VERSION ""

NS_ :

BS_:

BU_: VESC1 Main_ECU

BO_ 2147483649 VESC_Command_DutyCycle_V1: 4 Main_ECU
 SG_ Command_DutyCycle_V1 : 7|32@0- (0.001,0) [-100|100] "%"  VESC1

BO_ 2147486721 VESC_Command_AbsHBrakeCurrent_V1: 8 Main_ECU
 SG_ Command_HBrakeCurrent_V1 : 7|32@0- (0.001,0) [-2147483.648|2147483.647] "mA"  VESC1

BO_ 2147486977 VESC_Command_RelHBrakeCurrent_V1: 8 Main_ECU
 SG_ Command_RelativeHBrakeCurrent_V1 : 7|32@0- (0.001,0) [-100|100] "%"  VESC1

BO_ 2147489281 VESC_Set_CurrentLimitPerm_V1: 8 Main_ECU
 SG_ Setting_CurrentLimitMin_V1 : 7|32@0- (0.001,0) [-2147483.648|2147483.647] ""  VESC1
 SG_ Setting_CurrentLimitMax_V1 : 39|32@0- (0.001,0) [-2147483.648|2147483.647] ""  VESC1

BO_ 2147489025 VESC_Set_CurrentLimitTemp_V1: 8 Main_ECU
 SG_ Setting_CurrentLimitMin_V1 : 7|32@0- (0.001,0) [-2147483.648|2147483.647] ""  VESC1
 SG_ Setting_CurrentLimitMax_V1 : 39|32@0- (0.001,0) [-2147483.648|2147483.647] ""  VESC1

BO_ 2147486465 VESC_Command_RelBrakeCurrent_V1: 4 Main_ECU
 SG_ Command_RelativeBrakeCurrent_V1 : 7|32@0- (0.001,0) [-100|100] "%"  VESC1

BO_ 2147486209 VESC_Command_RelCurrent_V1: 4 Main_ECU
 SG_ Command_RelativeCurrent_V1 : 7|32@0- (0.001,0) [-100|100] "%"  VESC1

BO_ 2147484673 VESC_Command_POS_V1: 4 Main_ECU
 SG_ Command_POS_V1 : 7|32@0- (1,0) [-2147483648|2147483647] "RPM"  VESC1

BO_ 2147484161 VESC_Command_AbsBrakeCurrent_V1: 4 Main_ECU
 SG_ Command_BrakeCurrent_V1 : 7|32@0- (0.001,0) [-2147483.648|2147483.647] "mA"  VESC1

BO_ 2147483905 VESC_Command_AbsCurrent_V1: 4 Main_ECU
 SG_ Command_Current_V1 : 7|32@0- (0.001,0) [-2147483.648|2147483.647] "mA"  VESC1

BO_ 2147484417 VESC_Command_RPM_V1: 4 Main_ECU
 SG_ Command_RPM_V1 : 7|32@0- (1,0) [-2147483648|2147483647] "RPM"  VESC1

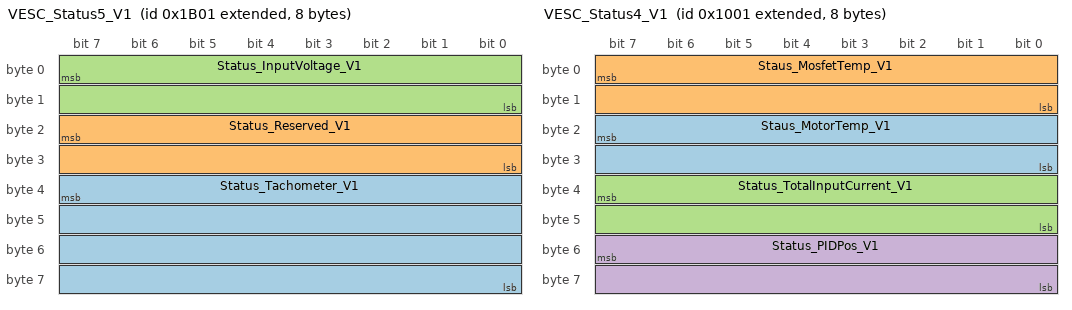
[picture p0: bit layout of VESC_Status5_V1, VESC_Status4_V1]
BO_ 2147490561 VESC_Status5_V1: 8 VESC1
 SG_ Status_Tachometer_V1 : 39|32@0- (1,0) [0|0] "RPM"  Main_ECU
 SG_ Status_Reserved_V1 : 23|16@0- (1,0) [0|0] ""  Main_ECU
 SG_ Status_InputVoltage_V1 : 7|16@0- (0.1,0) [0|0] ""  Main_ECU

BO_ 2147487745 VESC_Status4_V1: 8 VESC1
 SG_ Staus_MotorTemp_V1 : 23|16@0- (0.1,0) [-3276.8|3276.7] " C"  Main_ECU
 SG_ Staus_MosfetTemp_V1 : 7|16@0- (0.1,0) [-3276.8|3276.7] " C"  Main_ECU
 SG_ Status_TotalInputCurrent_V1 : 39|16@0- (0.1,0) [-3276.8|3276.7] "A"  Main_ECU
 SG_ Status_PIDPos_V1 : 55|16@0- (0.02,0) [-655.36|655.34] ""  Main_ECU

BO_ 2147487489 VESC_Status3_V1: 8 VESC1
 SG_ Status_WattHoursCharged_V1 : 39|32@0- (1E-005,0) [-21474.83648|21474.83647] "Wh"  Main_ECU
 SG_ Status_WattHours_V1 : 7|32@0- (1E-005,0) [-21474.83648|21474.83647] "Wh"  Main_ECU

BO_ 2147487233 VESC_Status2_V1: 8 VESC1
 SG_ Status_AmpHoursCharged_V1 : 39|32@0- (1E-005,0) [-21474.83648|21474.83647] "Ah"  Main_ECU
 SG_ Status_AmpHours_V1 : 7|32@0- (1E-005,0) [-21474.83648|21474.83647] "Ah"  Main_ECU

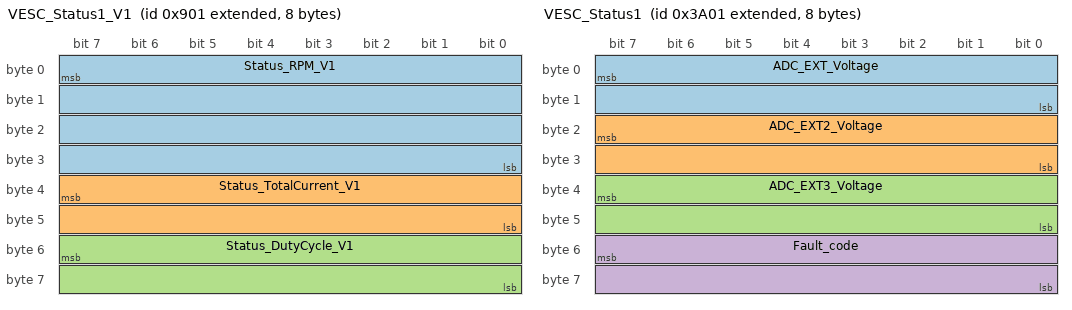
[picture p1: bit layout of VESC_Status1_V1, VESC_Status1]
BO_ 2147485953 VESC_Status1_V1: 8 VESC1
 SG_ Status_RPM_V1 : 7|32@0- (1,0) [-2147483648|2147483647] "RPM"  Main_ECU
 SG_ Status_TotalCurrent_V1 : 39|16@0- (0.1,0) [-3276.8|3276.7] "A"  Main_ECU
 SG_ Status_DutyCycle_V1 : 55|16@0- (0.1,0) [-100|100] "%"  Main_ECU

BO_ 2147498497 VESC_Status1: 8 VESC1
 SG_ ADC_EXT_Voltage : 7|16@0- (0.001,0) [0|65.535] "V" Main_ECU
 SG_ ADC_EXT2_Voltage : 23|16@0- (0.001,0) [0|65.535] "V" Main_ECU
 SG_ ADC_EXT3_Voltage : 39|16@0- (0.001,0) [0|65.535] "V" Main_ECU
 SG_ Fault_code : 55|16@0- (1,0) [0| 100] "Code" Main_ECU

BA_DEF_  "BusType" STRING ;
BA_DEF_DEF_  "BusType" "CAN";
